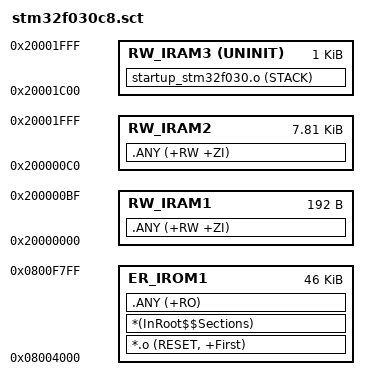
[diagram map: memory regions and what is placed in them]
; *************************************************************
; *** Scatter-Loading Description File generated by uVision ***
; *************************************************************

LR_IROM1 0x08004000 0x0000B800  {    ; load region size_region
  ER_IROM1 0x08004000 0x0000B800  {  ; load address = execution address
   *.o (RESET, +First)
   *(InRoot$$Sections)
   .ANY (+RO)
  }
  
  RW_IRAM1 0x20000000 0x000000C0  {  ; RW data
   .ANY (+RW +ZI)
  }
  
  RW_IRAM2 0x200000C0 0x00001F40  {
   .ANY (+RW +ZI)
  }
  
  RW_IRAM3 0x20001C00 UNINIT 0x00000400 { ; STACK ADDRESS
   startup_stm32f030.o (STACK)
  }
}

